# HDSC_HC32M140FX register map
Vendor: HDSC Co.Ltd; Series: ARMCM0P; File version: 1.2
CPU: CM0 r0p0, little endian, no MPU, no FPU, 3 interrupt priority bits
Registers are 8-bit, read-write, reset 0x0 unless marked. A register's access mark holds for its fields unless they carry their own. Offsets are from the block's base; lines under a group give offsets from that group; [hi:lo] are bit positions; {n}, {i} and the like mark numbered series; 'fields as' and 'values as' point back to an identical list; <NAME> marks a mode.

## Memory map
0x40000000 FLASH_IF size 0x42
0x40000100 UID size 0xC
0x40010000 CLOCK size 0x69
0x40011000 HWWDT size 0x18
0x40012000 SWWDT size 0xC04
0x40015000 DTIM1 size 0x1C — desc DTIM
0x40015020 DTIM2 size 0x1C — desc DTIM
0x40020000 TIMER4 size 0xF2
0x40025000 CT0_PPG size 0x12 — desc CT_PPG
0x40025000 CT0_PWC size 0x12 — desc CT_PWC
0x40025000 CT0_PWM size 0x12 — desc CT_PWM
0x40025000 CT0_RT size 0x12 — desc CT_RT
0x40025040 CT1_PPG size 0x12 — desc CT_PPG
0x40025040 CT1_PWC size 0x12 — desc CT_PWC
0x40025040 CT1_PWM size 0x12 — desc CT_PWM
0x40025040 CT1_RT size 0x12 — desc CT_RT
0x40025080 CT2_PPG size 0x12 — desc CT_PPG
0x40025080 CT2_PWC size 0x12 — desc CT_PWC
0x40025080 CT2_PWM size 0x12 — desc CT_PWM
0x40025080 CT2_RT size 0x12 — desc CT_RT
0x400250C0 CT3_PPG size 0x12 — desc CT_PPG
0x400250C0 CT3_PWC size 0x12 — desc CT_PWC
0x400250C0 CT3_PWM size 0x12 — desc CT_PWM
0x400250C0 CT3_RT size 0x12 — desc CT_RT
0x40025100 CTIOSEL03 size 0x2
0x40025F00 CTSSSR size 0xFD
0x40027000 ADC size 0x58
0x4002E000 OSC_CTL size 0x34
0x40030000 EXTINT size 0x1A
0x40031000 IRQC size 0x94
0x40033000 GPIO size 0x920
0x40035000 WSUNIT size 0x716
0x40037000 MSC4_I2C size 0x52 — desc MSC_I2C
0x40037000 MSC4_SPI size 0x52 — desc MSC_SPI
0x40037000 MSC4_UART size 0x52 — desc MSC_UART
0x40037100 MSC5_I2C size 0x52 — desc MSC_I2C
0x40037100 MSC5_SPI size 0x52 — desc MSC_SPI
0x40037100 MSC5_UART size 0x52 — desc MSC_UART
0x40037200 MSC6_I2C size 0x52 — desc MSC_I2C
0x40037200 MSC6_SPI size 0x52 — desc MSC_SPI
0x40037200 MSC6_UART size 0x52 — desc MSC_UART
0x4003A000 CLOCK_COUNTER size 0x15
0x4003C000 PARITY size 0x8
0x4003C100 PCG size 0x28
0x4003C300 VC size 0x9
0x4003C400 OPA0 size 0x1 — desc OPA
0x4003C480 OPA1 size 0x1 — desc OPA
0x40060000 DMAC size 0x30
0xF0001000 MTB_DWT size 0x1000
0xF8000000 FASTIO size 0x60

## ADC
Base 0x40027000
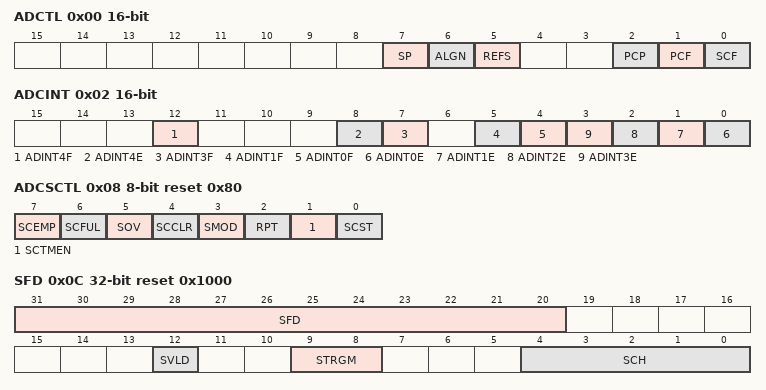
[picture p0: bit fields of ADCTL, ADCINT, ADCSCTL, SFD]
0x00 ADCTL 16-bit
  [7] SP, [6] ALGN, [5] REFS, [2] PCP ro, [1] PCF ro, [0] SCF ro
0x02 ADCINT 16-bit
  [12] ADINT4F, [8] ADINT4E, [7] ADINT3F, [5] ADINT1F, [4] ADINT0F, [n] ADINT{n}E (n=0..3)
0x08 ADCSCTL reset 0x80
  [7] SCEMP ro, [6] SCFUL ro, [5] SOV, [4] SCCLR, [3] SMOD, [2] RPT, [1] SCTMEN, [0] SCST
0x09 SFS
  [3:0] SDPTH
0x0C SFD 32-bit ro reset 0x1000
  [31:20] SFD, [12] SVLD, [9:8] STRGM, [4:0] SCH
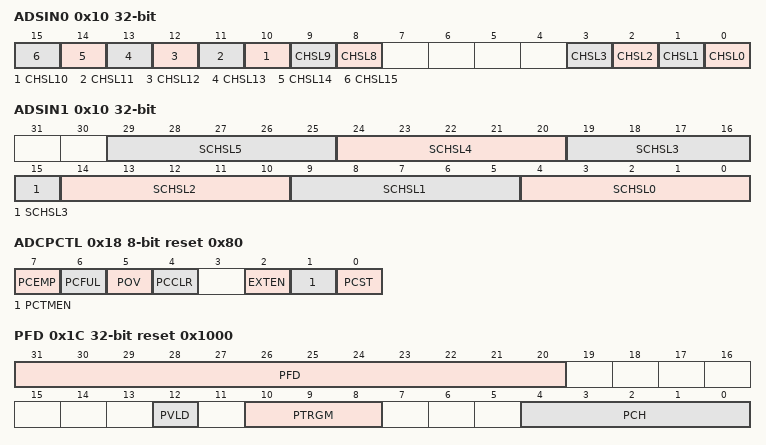
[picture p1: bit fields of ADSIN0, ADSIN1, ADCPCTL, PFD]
0x10 ADSIN0 32-bit
  [n] CHSL{n} (n=8..15), [n] CHSL{n} (n=0..3)
0x10 ADSIN1 32-bit
  [5n+4:5n] SCHSL{n} (n=0..5)
0x18 ADCPCTL reset 0x80
  [7] PCEMP ro, [6] PCFUL ro, [5] POV, [4] PCCLR, [2] EXTEN, [1] PCTMEN, [0] PCST
0x19 PFS
  [1:0] PDPTH
0x1C PFD 32-bit ro reset 0x1000
  [31:20] PFD, [12] PVLD, [10:8] PTRGM, [4:0] PCH
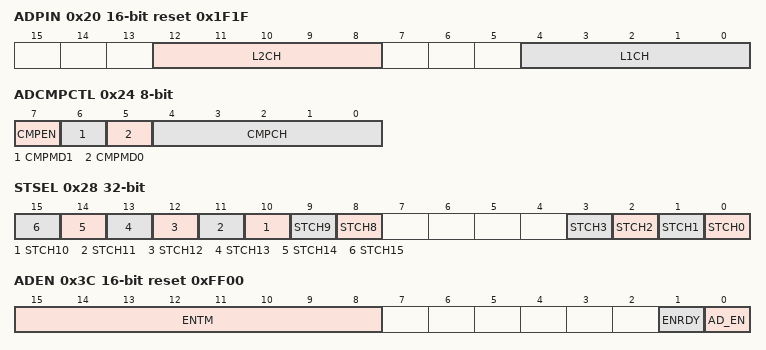
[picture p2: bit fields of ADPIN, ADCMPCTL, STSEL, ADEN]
0x20 ADPIN 16-bit reset 0x1F1F
  [12:8] L2CH, [4:0] L1CH
0x24 ADCMPCTL
  [7] CMPEN, [6] CMPMD1, [5] CMPMD0, [4:0] CMPCH
0x26 ADCMPD 16-bit
  [15:6] CD
0x28 STSEL 32-bit
  [n] STCH{n} (n=8..15), [n] STCH{n} (n=0..3)
0x30 STS0 reset 0x2
  [1:0] TM0
0x31 STS1 reset 0x2
  [1:0] TM1
0x34 ADCDIV reset 0x1
  [6:0] DIV
0x38 ADCSTSL
  [3:0] STRGIN
0x39 ADCPTSL
  [3:0] PTRGIN
0x3C ADEN 16-bit reset 0xFF00
  [15:8] ENTM, [1] ENRDY ro, [0] AD_EN
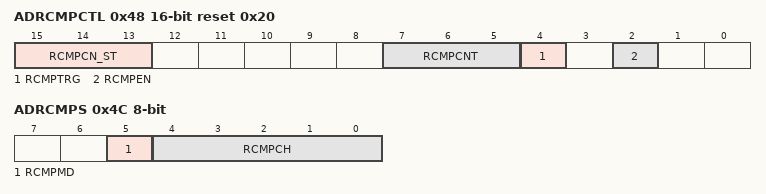
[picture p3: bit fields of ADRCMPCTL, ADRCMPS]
0x48 ADRCMPCTL 16-bit reset 0x20
  [15:13] RCMPCN_ST ro, [7:5] RCMPCNT, [4] RCMPTRG, [2] RCMPEN
0x4C ADRCMPS
  [5] RCMPMD, [4:0] RCMPCH
0x50 ADRCMPL 16-bit
  [15:6] CDL
0x52 ADRCMPH 16-bit
  [15:6] CDH
0x54 ADRCMPF 32-bit ro
  [0] RCMPF

## CLOCK
Base 0x40010000
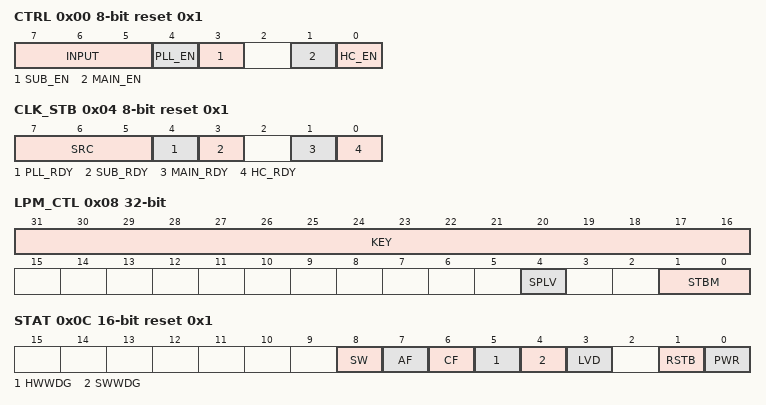
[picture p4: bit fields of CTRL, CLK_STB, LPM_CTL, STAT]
0x00 CTRL reset 0x1
  [7:5] INPUT, [4] PLL_EN, [3] SUB_EN, [1] MAIN_EN, [0] HC_EN
0x04 CLK_STB ro reset 0x1
  [7:5] SRC, [4] PLL_RDY, [3] SUB_RDY, [1] MAIN_RDY, [0] HC_RDY
0x08 LPM_CTL 32-bit
  [31:16] KEY, [4] SPLV, [1:0] STBM
0x0C STAT 16-bit ro reset 0x1
  [8] SW, [7] AF, [6] CF, [5] HWWDG, [4] SWWDG, [3] LVD, [1] RSTB, [0] PWR
0x10 BC_DIV
  [2:0] DIV
0x14 APB0_CTRL
  [1:0] DIV
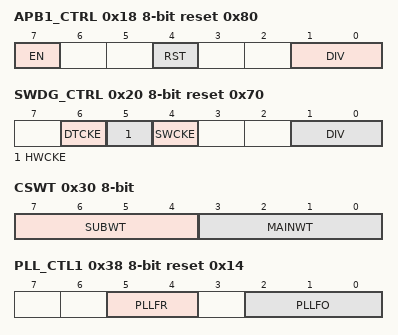
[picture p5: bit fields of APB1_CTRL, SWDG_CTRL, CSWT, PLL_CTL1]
0x18 APB1_CTRL reset 0x80
  [7] EN, [4] RST, [1:0] DIV
0x20 SWDG_CTRL reset 0x70
  [6] DTCKE, [5] HWCKE, [4] SWCKE, [1:0] DIV
0x30 CSWT
  [7:4] SUBWT, [3:0] MAINWT
0x34 PSWT
  [1:0] PLLWT
0x38 PLL_CTL1 reset 0x14
  [5:4] PLLFR, [2:0] PLLFO
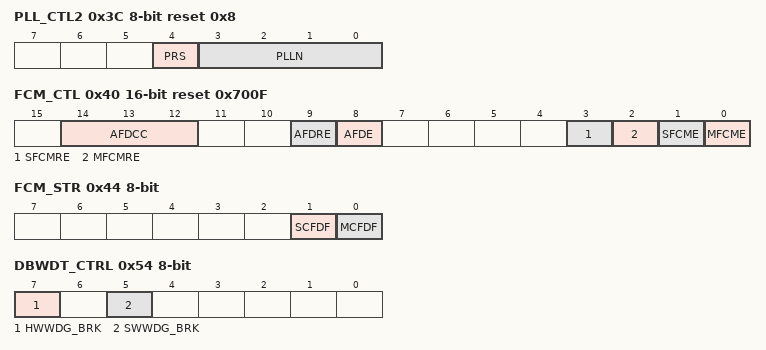
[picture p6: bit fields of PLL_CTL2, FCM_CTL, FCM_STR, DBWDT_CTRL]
0x3C PLL_CTL2 reset 0x8
  [4] PRS, [3:0] PLLN
0x40 FCM_CTL 16-bit reset 0x700F
  [14:12] AFDCC, [9] AFDRE, [8] AFDE, [3] SFCMRE, [2] MFCMRE, [1] SFCME, [0] MFCME
0x44 FCM_STR ro
  [1] SCFDF, [0] MCFDF
0x48 AFDWH 16-bit reset 0xFFFF
0x4C AFDWL 16-bit
0x50 AFDC 16-bit ro
0x54 DBWDT_CTRL
  [7] HWWDG_BRK, [5] SWWDG_BRK
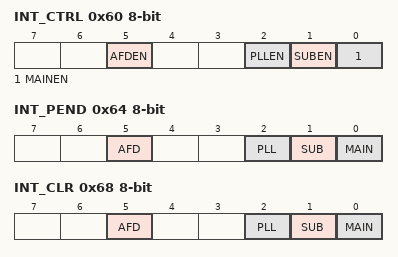
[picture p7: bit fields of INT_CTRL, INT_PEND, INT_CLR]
0x60 INT_CTRL
  [5] AFDEN, [2] PLLEN, [1] SUBEN, [0] MAINEN
0x64 INT_PEND ro
  [5] AFD, [2] PLL, [1] SUB, [0] MAIN
0x68 INT_CLR wo
  [5] AFD, [2] PLL, [1] SUB, [0] MAIN
